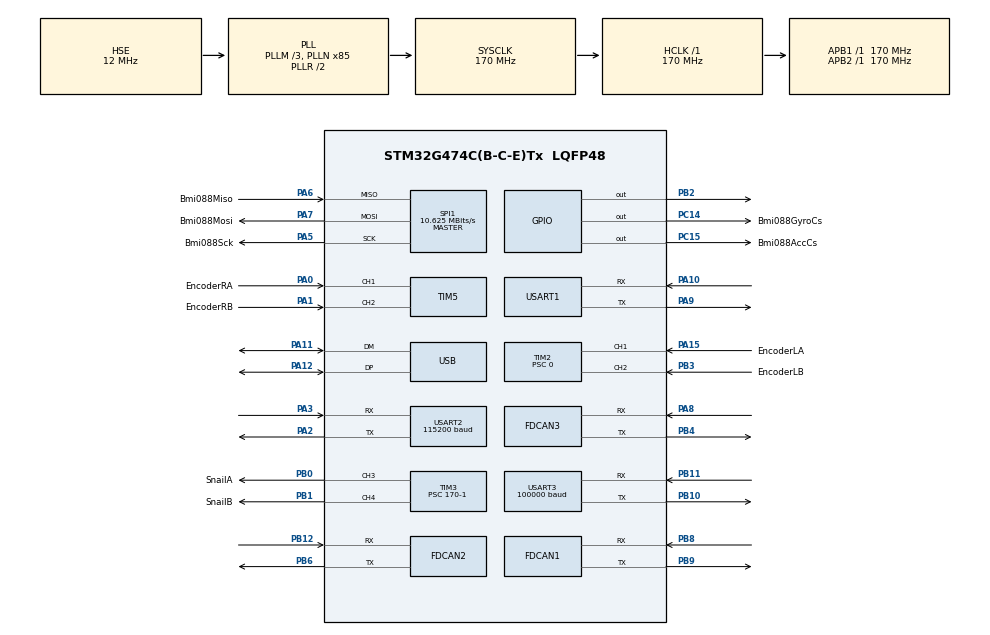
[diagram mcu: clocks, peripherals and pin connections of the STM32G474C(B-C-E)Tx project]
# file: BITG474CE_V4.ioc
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Dma.Request0=USART2_RX
Dma.Request1=USART2_TX
Dma.Request2=USART3_RX
Dma.USART2_RX.0.Direction=DMA_PERIPH_TO_MEMORY
Dma.USART2_RX.0.EventEnable=DISABLE
Dma.USART2_RX.0.Instance=DMA1_Channel3
Dma.USART2_RX.0.MemDataAlignment=DMA_MDATAALIGN_BYTE
Dma.USART2_RX.0.MemInc=DMA_MINC_ENABLE
Dma.USART2_RX.0.Mode=DMA_CIRCULAR
Dma.USART2_RX.0.PeriphDataAlignment=DMA_PDATAALIGN_BYTE
Dma.USART2_RX.0.PeriphInc=DMA_PINC_DISABLE
Dma.USART2_RX.0.Polarity=HAL_DMAMUX_REQ_GEN_RISING
Dma.USART2_RX.0.Priority=DMA_PRIORITY_LOW
Dma.USART2_RX.0.RequestNumber=1
Dma.USART2_RX.0.SignalID=NONE
Dma.USART2_RX.0.SyncEnable=DISABLE
Dma.USART2_RX.0.SyncPolarity=HAL_DMAMUX_SYNC_NO_EVENT
Dma.USART2_RX.0.SyncRequestNumber=1
Dma.USART2_RX.0.SyncSignalID=NONE
Dma.USART2_TX.1.Direction=DMA_MEMORY_TO_PERIPH
Dma.USART2_TX.1.EventEnable=DISABLE
Dma.USART2_TX.1.Instance=DMA1_Channel1
Dma.USART2_TX.1.MemDataAlignment=DMA_MDATAALIGN_BYTE
Dma.USART2_TX.1.MemInc=DMA_MINC_ENABLE
Dma.USART2_TX.1.Mode=DMA_NORMAL
Dma.USART2_TX.1.PeriphDataAlignment=DMA_PDATAALIGN_BYTE
Dma.USART2_TX.1.PeriphInc=DMA_PINC_DISABLE
Dma.USART2_TX.1.Polarity=HAL_DMAMUX_REQ_GEN_RISING
Dma.USART2_TX.1.Priority=DMA_PRIORITY_LOW
Dma.USART2_TX.1.RequestNumber=1
Dma.USART2_TX.1.SignalID=NONE
Dma.USART2_TX.1.SyncEnable=DISABLE
Dma.USART2_TX.1.SyncPolarity=HAL_DMAMUX_SYNC_NO_EVENT
Dma.USART2_TX.1.SyncRequestNumber=1
Dma.USART2_TX.1.SyncSignalID=NONE
Dma.USART3_RX.2.Direction=DMA_PERIPH_TO_MEMORY
Dma.USART3_RX.2.EventEnable=DISABLE
Dma.USART3_RX.2.Instance=DMA1_Channel6
Dma.USART3_RX.2.MemDataAlignment=DMA_MDATAALIGN_BYTE
Dma.USART3_RX.2.MemInc=DMA_MINC_ENABLE
Dma.USART3_RX.2.Mode=DMA_NORMAL
Dma.USART3_RX.2.PeriphDataAlignment=DMA_PDATAALIGN_BYTE
Dma.USART3_RX.2.PeriphInc=DMA_PINC_DISABLE
Dma.USART3_RX.2.Polarity=HAL_DMAMUX_REQ_GEN_RISING
Dma.USART3_RX.2.Priority=DMA_PRIORITY_LOW
Dma.USART3_RX.2.RequestNumber=1
Dma.USART3_RX.2.SignalID=NONE
Dma.USART3_RX.2.SyncEnable=DISABLE
Dma.USART3_RX.2.SyncPolarity=HAL_DMAMUX_SYNC_NO_EVENT
Dma.USART3_RX.2.SyncRequestNumber=1
Dma.USART3_RX.2.SyncSignalID=NONE
FDCAN1.AutoRetransmission=DISABLE
FDCAN1.CalculateBaudRateNominal=1000000
FDCAN1.CalculateTimeBitNominal=1000
FDCAN1.CalculateTimeQuantumNominal=100.0
FDCAN1.DataPrescaler=2
FDCAN1.DataTimeSeg1=10
FDCAN1.DataTimeSeg2=6
FDCAN1.ExtFiltersNbr=8
FDCAN1.FrameFormat=FDCAN_FRAME_FD_BRS
FDCAN1.Mode=FDCAN_MODE_NORMAL
FDCAN1.NominalPrescaler=17
FDCAN1.NominalTimeSeg1=6
FDCAN1.NominalTimeSeg2=3
FDCAN1.ProtocolException=ENABLE
FDCAN1.StdFiltersNbr=8
FDCAN1.TransmitPause=ENABLE
FDCAN1.TxFifoQueueMode=FDCAN_TX_FIFO_OPERATION
FDCAN2.AutoRetransmission=DISABLE
FDCAN2.CalculateBaudRateNominal=1000000
FDCAN2.CalculateTimeBitNominal=1000
FDCAN2.CalculateTimeQuantumNominal=100.0
FDCAN2.DataPrescaler=2
FDCAN2.DataTimeSeg1=10
FDCAN2.DataTimeSeg2=6
FDCAN2.ExtFiltersNbr=8
FDCAN2.FrameFormat=FDCAN_FRAME_FD_BRS
FDCAN2.Mode=FDCAN_MODE_NORMAL
FDCAN2.NominalPrescaler=17
FDCAN2.NominalTimeSeg1=6
FDCAN2.NominalTimeSeg2=3
FDCAN2.ProtocolException=ENABLE
FDCAN2.StdFiltersNbr=8
FDCAN2.TransmitPause=ENABLE
FDCAN3.AutoRetransmission=DISABLE
FDCAN3.CalculateBaudRateNominal=3400000
FDCAN3.CalculateTimeBitNominal=294
FDCAN3.CalculateTimeQuantumNominal=29.411764705882355
FDCAN3.DataPrescaler=2
FDCAN3.DataTimeSeg1=10
FDCAN3.DataTimeSeg2=6
FDCAN3.ExtFiltersNbr=8
FDCAN3.FrameFormat=FDCAN_FRAME_FD_BRS
FDCAN3.Mode=FDCAN_MODE_NORMAL
FDCAN3.NominalPrescaler=5
FDCAN3.NominalTimeSeg1=6
FDCAN3.NominalTimeSeg2=3
FDCAN3.ProtocolException=ENABLE
FDCAN3.StdFiltersNbr=8
FDCAN3.TransmitPause=ENABLE
FREERTOS.Tasks01=defaultTask,0,128,StartDefaultTask,Default,NULL,Dynamic,NULL,NULL
Mcu.Family=STM32G4
Mcu.Name=STM32G474C(B-C-E)Tx
Mcu.Package=LQFP48
NVIC.DMA1_Channel1_IRQn=true\:5\:0\:false\:false\:true\:true\:false\:true\:true
NVIC.DMA1_Channel3_IRQn=true\:5\:0\:false\:false\:true\:true\:false\:true\:true
NVIC.DMA1_Channel6_IRQn=true\:5\:0\:false\:false\:true\:true\:false\:true\:true
NVIC.FDCAN1_IT0_IRQn=true\:5\:0\:false\:false\:true\:true\:true\:true\:true
NVIC.FDCAN2_IT0_IRQn=true\:5\:0\:false\:false\:true\:true\:true\:true\:true
NVIC.FDCAN3_IT0_IRQn=true\:5\:0\:false\:false\:true\:true\:true\:true\:true
NVIC.PVD_PVM_IRQn=true\:5\:0\:false\:false\:true\:true\:true\:true\:true
NVIC.PriorityGroup=NVIC_PRIORITYGROUP_4
NVIC.TIM2_IRQn=true\:5\:0\:false\:false\:false\:true\:true\:true\:true
NVIC.TIM8_CC_IRQn=true\:5\:0\:false\:false\:false\:true\:true\:true\:true
NVIC.USART1_IRQn=true\:5\:0\:false\:false\:true\:true\:true\:true\:true
NVIC.USART2_IRQn=true\:5\:0\:false\:false\:true\:true\:true\:true\:true
NVIC.USART3_IRQn=true\:5\:0\:false\:false\:true\:true\:true\:true\:true
NVIC.USB_LP_IRQn=true\:5\:0\:false\:false\:true\:true\:true\:true\:true
PA0.GPIO_Label=EncoderRA
PA0.Signal=S_TIM5_CH1
PA1.GPIO_Label=EncoderRB
PA1.Signal=S_TIM5_CH2
PA10.Mode=Asynchronous
PA10.Signal=USART1_RX
PA11.Mode=Device
PA11.Signal=USB_DM
PA12.Mode=Device
PA12.Signal=USB_DP
PA13.Mode=Serial_Wire
PA13.Signal=SYS_JTMS-SWDIO
PA14.Mode=Serial_Wire
PA14.Signal=SYS_JTCK-SWCLK
PA15.GPIO_Label=EncoderLA
PA15.Signal=S_TIM2_CH1
PA2.Mode=Asynchronous
PA2.Signal=USART2_TX
PA3.Mode=Asynchronous
PA3.Signal=USART2_RX
PA5.GPIO_Label=Bmi088Sck
PA5.Mode=Full_Duplex_Master
PA5.Signal=SPI1_SCK
PA6.GPIO_Label=Bmi088Miso
PA6.Mode=Full_Duplex_Master
PA6.Signal=SPI1_MISO
PA7.GPIO_Label=Bmi088Mosi
PA7.Mode=Full_Duplex_Master
PA7.Signal=SPI1_MOSI
PA8.Mode=FDCAN_Activate
PA8.Signal=FDCAN3_RX
PA9.Mode=Asynchronous
PA9.Signal=USART1_TX
PB0.GPIO_Label=SnailA
PB0.Signal=S_TIM3_CH3
PB1.GPIO_Label=SnailB
PB1.Signal=S_TIM3_CH4
PB10.Mode=Asynchronous
PB10.Signal=USART3_TX
PB11.Mode=Asynchronous
PB11.Signal=USART3_RX
PB12.Mode=FDCAN_Activate
PB12.Signal=FDCAN2_RX
PB2.Signal=GPIO_Output
PB3.GPIO_Label=EncoderLB
PB3.Signal=S_TIM2_CH2
PB4.Mode=FDCAN_Activate
PB4.Signal=FDCAN3_TX
PB6.Mode=FDCAN_Activate
PB6.Signal=FDCAN2_TX
PB8-BOOT0.Mode=FDCAN_Activate
PB8-BOOT0.Signal=FDCAN1_RX
PB9.Mode=FDCAN_Activate
PB9.Signal=FDCAN1_TX
PC14-OSC32_IN.GPIO_Label=Bmi088GyroCs
PC14-OSC32_IN.PinState=GPIO_PIN_SET
PC14-OSC32_IN.Signal=GPIO_Output
PC15-OSC32_OUT.GPIO_Label=Bmi088AccCs
PC15-OSC32_OUT.PinState=GPIO_PIN_SET
PC15-OSC32_OUT.Signal=GPIO_Output
PF0-OSC_IN.Mode=HSE-External-Oscillator
PF0-OSC_IN.Signal=RCC_OSC_IN
PF1-OSC_OUT.Mode=HSE-External-Oscillator
PF1-OSC_OUT.Signal=RCC_OSC_OUT
ProjectManager.HeapSize=0x1000
ProjectManager.StackSize=0x4000
ProjectManager.TargetToolchain=CMake
RCC.ADC12Freq_Value=170000000
RCC.ADC345Freq_Value=170000000
RCC.AHBFreq_Value=170000000
RCC.APB1Freq_Value=170000000
RCC.APB1TimFreq_Value=170000000
RCC.APB2Freq_Value=170000000
RCC.APB2TimFreq_Value=170000000
RCC.CK48CLockSelection=RCC_USBCLKSOURCE_HSI48
RCC.CortexFreq_Value=170000000
RCC.EXTERNAL_CLOCK_VALUE=12288000
RCC.HCLKFreq_Value=170000000
RCC.HSE_VALUE=12000000
RCC.HSI48_VALUE=48000000
RCC.HSI_VALUE=16000000
RCC.LSE_VALUE=32768
RCC.PLLM=RCC_PLLM_DIV3
RCC.PLLN=85
RCC.PLLQ=RCC_PLLQ_DIV4
RCC.PLLSourceVirtual=RCC_PLLSOURCE_HSE
RCC.SYSCLKFreq_VALUE=170000000
RCC.SYSCLKSource=RCC_SYSCLKSOURCE_PLLCLK
RCC.USBFreq_Value=48000000
RCC.VCOOutputFreq_Value=340000000
SH.S_TIM2_CH1.0=TIM2_CH1,Encoder_Interface
SH.S_TIM2_CH2.0=TIM2_CH2,Encoder_Interface
SH.S_TIM3_CH3.0=TIM3_CH3,PWM Generation3 CH3
SH.S_TIM3_CH4.0=TIM3_CH4,PWM Generation4 CH4
SH.S_TIM5_CH1.0=TIM5_CH1,Encoder_Interface
SH.S_TIM5_CH2.0=TIM5_CH2,Encoder_Interface
SPI1.BaudRatePrescaler=SPI_BAUDRATEPRESCALER_16
SPI1.CLKPhase=SPI_PHASE_2EDGE
SPI1.CLKPolarity=SPI_POLARITY_HIGH
SPI1.CalculateBaudRate=10.625 MBits/s
SPI1.DataSize=SPI_DATASIZE_8BIT
SPI1.Direction=SPI_DIRECTION_2LINES
SPI1.Mode=SPI_MODE_MASTER
SPI1.VirtualType=VM_MASTER
STMicroelectronics.X-CUBE-AZRTOS-G4.2.0.0.TX_APP_GENERATE_INIT_CODE=true
STMicroelectronics.X-CUBE-AZRTOS-G4.2.0.0.TX_MINIMUM_STACK=210
STMicroelectronics.X-CUBE-AZRTOS-G4.2.0.0.TX_TIMER_TICKS_PER_SECOND=1000
STMicroelectronics.X-CUBE-AZRTOS-G4.2.0.0_IsAnAzureRtosMw=true
TIM2.AutoReloadPreload=TIM_AUTORELOAD_PRELOAD_DISABLE
TIM2.EncoderMode=TIM_ENCODERMODE_TI12
TIM2.IC1Filter=5
TIM2.IC2Filter=5
TIM2.PeriodNoDither=0xFFFFFFFF
TIM2.Prescaler=0
TIM3.Channel-PWM\ Generation3\ CH3=TIM_CHANNEL_3
TIM3.Channel-PWM\ Generation4\ CH4=TIM_CHANNEL_4
TIM3.PeriodNoDither=1999
TIM3.Prescaler=170-1
TIM3.PulseNoDither_3=2000
TIM3.PulseNoDither_4=2000
TIM5.EncoderMode=TIM_ENCODERMODE_TI12
TIM5.IC1Filter=5
TIM5.IC2Filter=5
TIM8.AutoReloadPreload=TIM_AUTORELOAD_PRELOAD_ENABLE
TIM8.Channel-Output\ Compare1\ No\ Output=TIM_CHANNEL_1
TIM8.Channel-Output\ Compare2\ No\ Output=TIM_CHANNEL_2
TIM8.Channel-Output\ Compare3\ No\ Output=TIM_CHANNEL_3
TIM8.Channel-Output\ Compare4\ No\ Output=TIM_CHANNEL_4
TIM8.Channel-Output\ Compare5\ No\ Output=TIM_CHANNEL_5
TIM8.Channel-Output\ Compare6\ No\ Output=TIM_CHANNEL_6
TIM8.OCMode_1=TIM_OCMODE_ACTIVE
TIM8.OCMode_2=TIM_OCMODE_ACTIVE
TIM8.OCMode_3=TIM_OCMODE_ACTIVE
TIM8.OCMode_4=TIM_OCMODE_ACTIVE
TIM8.OCMode_5=TIM_OCMODE_ACTIVE
TIM8.OCMode_6=TIM_OCMODE_ACTIVE
TIM8.Prescaler=170-1
USART1.VirtualMode-Asynchronous=VM_ASYNC
USART2.BaudRate=115200
USART2.Parity=PARITY_NONE
USART2.VirtualMode-Asynchronous=VM_ASYNC
USART2.WordLength=WORDLENGTH_8B
USART3.BaudRate=100000
USART3.Parity=PARITY_EVEN
USART3.RxPinLevelInvertParam=ADVFEATURE_RXINV_ENABLE
USART3.VirtualMode-Asynchronous=VM_ASYNC
USART3.WordLength=WORDLENGTH_9B
USB_DEVICE.CLASS_NAME_FS=CDC
USB_DEVICE.VirtualMode=Cdc
USB_DEVICE.VirtualModeFS=Cdc_FS
VP_FREERTOS_VS_CMSIS_V1.Mode=CMSIS_V1
VP_SYS_VS_DBSignals.Mode=DisableDeadBatterySignals
VP_TIM8_VS_ClockSourceINT.Mode=Internal
VP_TIM8_VS_no_output1.Mode=Output Compare1 No Output
VP_TIM8_VS_no_output2.Mode=Output Compare2 No Output
VP_TIM8_VS_no_output3.Mode=Output Compare3 No Output
VP_TIM8_VS_no_output4.Mode=Output Compare4 No Output
VP_TIM8_VS_no_output5.Mode=Output Compare5 No Output
VP_TIM8_VS_no_output6.Mode=Output Compare6 No Output
VP_USB_DEVICE_VS_USB_DEVICE_CDC_FS.Mode=CDC_FS
board=custom

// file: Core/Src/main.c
/* USER CODE BEGIN Header */
/**
  ******************************************************************************
  * @file           : main.c
  * @brief          : Main program body
  ******************************************************************************
  * @attention
  *
  * Copyright (c) 2024 STMicroelectronics.
  * All rights reserved.
  *
  * This software is licensed under terms that can be found in the LICENSE file
  * in the root directory of this software component.
  * If no LICENSE file comes with this software, it is provided AS-IS.
  *
  ******************************************************************************
  */
/* USER CODE END Header */
#include "main.h"
#include "cmsis_os.h"
#include "dma.h"
#include "fdcan.h"
#include "spi.h"
#include "tim.h"
#include "usart.h"
#include "usb_device.h"
#include "gpio.h"

void SystemClock_Config(void);
void MX_FREERTOS_Init(void);

int main(void)
{

  /* MCU Configuration--------------------------------------------------------*/

  /* Reset of all peripherals, Initializes the Flash interface and the Systick. */
  HAL_Init();

  /* Configure the system clock */
  SystemClock_Config();

  /* Initialize all configured peripherals */
  MX_GPIO_Init();
  MX_DMA_Init();
  MX_FDCAN1_Init();
  MX_FDCAN2_Init();
  MX_FDCAN3_Init();
  MX_USART2_UART_Init();
  MX_TIM2_Init();
  MX_SPI1_Init();
  MX_USART3_UART_Init();
  MX_TIM3_Init();
  MX_TIM5_Init();
  MX_TIM8_Init();
  MX_USART1_UART_Init();

  /* Call init function for freertos objects (in cmsis_os2.c) */
  MX_FREERTOS_Init();

  /* Start scheduler */
  osKernelStart();

  /* We should never get here as control is now taken by the scheduler */

  /* Infinite loop */
  while (1)
  {

  }
}

void SystemClock_Config(void)
{
  RCC_OscInitTypeDef RCC_OscInitStruct = {0};
  RCC_ClkInitTypeDef RCC_ClkInitStruct = {0};

  /** Configure the main internal regulator output voltage
  */
  HAL_PWREx_ControlVoltageScaling(PWR_REGULATOR_VOLTAGE_SCALE1_BOOST);

  /** Initializes the RCC Oscillators according to the specified parameters
  * in the RCC_OscInitTypeDef structure.
  */
  RCC_OscInitStruct.OscillatorType = RCC_OSCILLATORTYPE_HSI48|RCC_OSCILLATORTYPE_HSE;
  RCC_OscInitStruct.HSEState = RCC_HSE_ON;
  RCC_OscInitStruct.HSI48State = RCC_HSI48_ON;
  RCC_OscInitStruct.PLL.PLLState = RCC_PLL_ON;
  RCC_OscInitStruct.PLL.PLLSource = RCC_PLLSOURCE_HSE;
  RCC_OscInitStruct.PLL.PLLM = RCC_PLLM_DIV3;
  RCC_OscInitStruct.PLL.PLLN = 85;
  RCC_OscInitStruct.PLL.PLLP = RCC_PLLP_DIV2;
  RCC_OscInitStruct.PLL.PLLQ = RCC_PLLQ_DIV4;
  RCC_OscInitStruct.PLL.PLLR = RCC_PLLR_DIV2;
  if (HAL_RCC_OscConfig(&RCC_OscInitStruct) != HAL_OK)
  {
    Error_Handler();
  }

  /** Initializes the CPU, AHB and APB buses clocks
  */
  RCC_ClkInitStruct.ClockType = RCC_CLOCKTYPE_HCLK|RCC_CLOCKTYPE_SYSCLK
                              |RCC_CLOCKTYPE_PCLK1|RCC_CLOCKTYPE_PCLK2;
  RCC_ClkInitStruct.SYSCLKSource = RCC_SYSCLKSOURCE_PLLCLK;
  RCC_ClkInitStruct.AHBCLKDivider = RCC_SYSCLK_DIV1;
  RCC_ClkInitStruct.APB1CLKDivider = RCC_HCLK_DIV1;
  RCC_ClkInitStruct.APB2CLKDivider = RCC_HCLK_DIV1;

  if (HAL_RCC_ClockConfig(&RCC_ClkInitStruct, FLASH_LATENCY_4) != HAL_OK)
  {
    Error_Handler();
  }
}

void Error_Handler(void)
{
  __disable_irq();
  while (1)
  {
  }
}

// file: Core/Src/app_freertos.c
/* USER CODE BEGIN Header */
/**
  ******************************************************************************
  * File Name          : app_freertos.c
  * Description        : Code for freertos applications
  ******************************************************************************
  * @attention
  *
  * Copyright (c) 2024 STMicroelectronics.
  * All rights reserved.
  *
  * This software is licensed under terms that can be found in the LICENSE file
  * in the root directory of this software component.
  * If no LICENSE file comes with this software, it is provided AS-IS.
  *
  ******************************************************************************
  */
/* USER CODE END Header */

#include "FreeRTOS.h"
#include "task.h"
#include "main.h"
#include "cmsis_os.h"

/* USER CODE BEGIN Includes */
#include "task/ins.h"
/* USER CODE END Includes */

osThreadId defaultTaskHandle;

void StartDefaultTask(void const * argument);

void MX_FREERTOS_Init(void); /* (MISRA C 2004 rule 8.1) */

void MX_FREERTOS_Init(void) {
  /* USER CODE BEGIN Init */
  InsTaskStart();;
  /* USER CODE END Init */

  /* Create the thread(s) */
  /* definition and creation of defaultTask */
  osThreadDef(defaultTask, StartDefaultTask, osPriorityNormal, 0, 128);
  defaultTaskHandle = osThreadCreate(osThread(defaultTask), NULL);

}

void StartDefaultTask(void const * argument)
{
  /* init code for USB_Device */
  // MX_USB_Device_Init();
  for(;;)
  {
    osDelay(1);
  }
}
